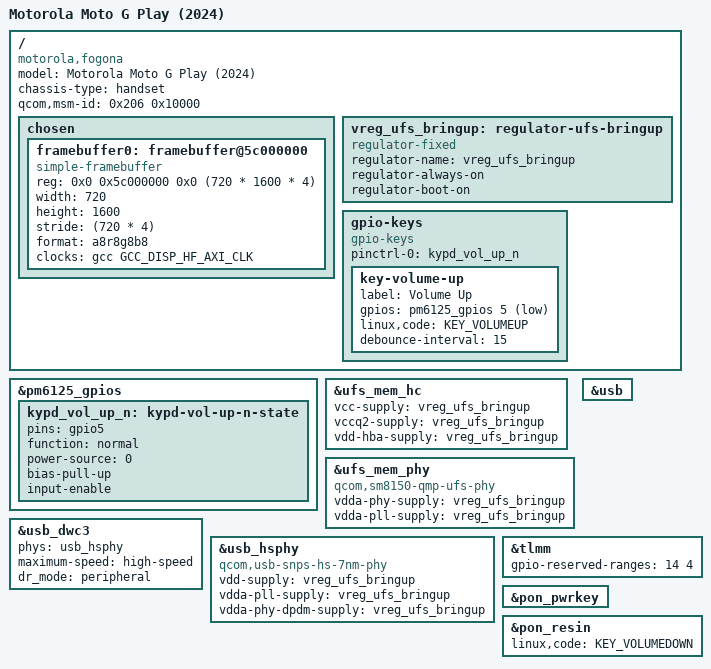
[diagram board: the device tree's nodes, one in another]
// SPDX-License-Identifier: BSD-3-Clause
/*
 * U-Boot board file: Motorola Moto G Play (2024) -- "fogona", SM6225 (khaje).
 *
 * Deliberately includes sm6115.dtsi and claims the sm6115 compatibles, because
 * U-Boot's Qualcomm support has clock-sm6115.c and pinctrl-sm6115.c and no
 * sm6225 equivalents. khaje is a bengal derivative, and mainline Linux's
 * gcc-sm6115 was confirmed to bind on this silicon (measured: it claimed the
 * clock controller at 0x1400000 and probed), so the same bet applies here.
 *
 * msm-id is measured, not inherited: /sys/devices/soc0/soc_id = 518 = 0x206,
 * revision 1.0. fogona ships two base DTBs differing only in this property
 * (0x24a and 0x206); this unit is 0x206.
 *
 * The framebuffer address is the same 0x5c000000 the fxtec sm6115 board uses,
 * confirmed on fogona from the live device tree
 * (splash_region@5c000000, 0xf00000) -- the panel is 720x1600 rather than
 * 1080x2160.
 */

/dts-v1/;

#include <dt-bindings/gpio/gpio.h>
#include <dt-bindings/input/linux-event-codes.h>
#include "sm6115.dtsi"
#include "pm6125.dtsi"

/ {
	model = "Motorola Moto G Play (2024)";
	compatible = "motorola,fogona", "qcom,sm6115";
	chassis-type = "handset";

	qcom,msm-id = <0x206 0x10000>;

	chosen {
		#address-cells = <2>;
		#size-cells = <2>;
		ranges;

		framebuffer0: framebuffer@5c000000 {
			compatible = "simple-framebuffer";
			reg = <0x0 0x5c000000 0x0 (720 * 1600 * 4)>;
			width = <720>;
			height = <1600>;
			stride = <(720 * 4)>;
			format = "a8r8g8b8";
			clocks = <&gcc GCC_DISP_HF_AXI_CLK>;
		};
	};
	/*
	 * UFS supplies. fogona's real rails are pm6125 LDOs behind RPM/SMD,
	 * which U-Boot has no driver for -- and ABL has already powered them,
	 * since it boots the device from UFS. An always-on fixed regulator is
	 * an honest stand-in for bringup.
	 */
	vreg_ufs_bringup: regulator-ufs-bringup {
		compatible = "regulator-fixed";
		regulator-name = "vreg_ufs_bringup";
		regulator-always-on;
		regulator-boot-on;
	};

	/*
	 * All three side keys are on the PM6125, none on TLMM. Power and
	 * volume-down come from the PON block (enabled at the end of this
	 * file); volume-up is PMIC GPIO 5.
	 *
	 * This node previously said <&tlmm 5>, which is the natural wrong
	 * guess and the one our Linux sm6225-motorola-fogona.dtsi explicitly
	 * warns about: the schematic routes KYPD_VOLP_N to PM6225 GPIO_05
	 * (pad 21), and the stock dtbo's vol_up node reads
	 * `gpios = <0xffffffff 0x05 0x01>` with a fixups block resolving that
	 * dangling phandle to pm6125_gpios. Read without applying the fixups
	 * it looks like a bare "gpio 5", and TLMM is the obvious misreading.
	 *
	 * Symptom of getting it wrong: volume-down works and volume-up does
	 * not, because down comes from PON and up reads a floating TLMM line.
	 *
	 * The pad also needs its pull-up: KYPD_VOLP_N is a switch to ground
	 * with no external pull, and the bootloader leaves the pad with the
	 * bias off, so the line floats while the key is up. Same state as
	 * the Linux dtsi, the stock dtbo (key_vol_up_default) and
	 * qrb4210-rb2.dts; the PMIC GPIO driver applies bias-pull-up and
	 * leaves it alone when the button driver later claims the line.
	 */
	gpio-keys {
		compatible = "gpio-keys";

		pinctrl-names = "default";
		pinctrl-0 = <&kypd_vol_up_n>;

		key-volume-up {
			label = "Volume Up";
			gpios = <&pm6125_gpios 5 GPIO_ACTIVE_LOW>;
			linux,code = <KEY_VOLUMEUP>;
			debounce-interval = <15>;
		};
	};
};

&pm6125_gpios {
	kypd_vol_up_n: kypd-vol-up-n-state {
		pins = "gpio5";
		function = "normal";
		power-source = <0>;
		bias-pull-up;
		input-enable;
	};
};

&ufs_mem_hc {
	vcc-supply = <&vreg_ufs_bringup>;
	vccq2-supply = <&vreg_ufs_bringup>;
	vdd-hba-supply = <&vreg_ufs_bringup>;
	status = "okay";
};

/*
 * Same class of mismatch as the USB HS PHY below: khaje's UFS QMP PHY is not
 * bengal's, and inheriting sm6115.dtsi gets us the wrong register tables.
 *
 * Unlike the USB case this one binds silently -- "qcom,sm6115-qmp-ufs-phy" IS
 * in U-Boot's match list, so the PHY programs without complaint and simply
 * never links, and `scsi scan` reports no devices with no error at all.
 *
 * Linux is explicit that these are different parts. In
 * phy-qcom-qmp-ufs.c, sm6125 aliases sm6115's config, but sm6225 gets its own:
 *
 *     sm6115: lanes 1, UFS_HS_G3, sm6115_ufsphy_* tables, v2 regs
 *     sm6225: lanes 2, UFS_HS_G4, sm8150_ufsphy_* tables, v4 regs
 *
 * and Linux's sm6225_ufsphy_cfg is field-for-field identical to its
 * sm8150_ufsphy_cfg -- a duplicated struct rather than a distinct PHY. U-Boot
 * has no "qcom,sm6225-qmp-ufs-phy", but it does carry sm8150_ufsphy_cfg with
 * the same 2 lanes, the same serdes/tx/rx/pcs tables and the same G4 overlay.
 *
 * So point at sm8150 and khaje gets exactly the tables Linux drives it with.
 * If a real qcom,sm6225-qmp-ufs-phy is ever added upstream, switch to it and
 * drop this override.
 */
&ufs_mem_phy {
	compatible = "qcom,sm8150-qmp-ufs-phy";
	vdda-phy-supply = <&vreg_ufs_bringup>;
	vdda-pll-supply = <&vreg_ufs_bringup>;
	status = "okay";
};

/*
 * USB. fogona is USB 2.0 only -- Motorola's schematics break out USB0_CC1/CC2
 * to testpoints but carry no SBU, and USB0_SS_* / USB0_DP_AUX_* have no
 * cross-sheet routing at all. So enable the HS phy and pin dwc3 to
 * high-speed, dropping the superspeed phy that sm6115.dtsi expects; otherwise
 * dwc3 waits on a qmpphy this board does not have.
 *
 * Supplies come from the bringup fixed regulator for the same reason as UFS:
 * the real rails are pm6125 LDOs behind RPM/SMD, and ABL has already brought
 * them up (it serves fastboot over this very port).
 */
&usb {
	status = "okay";
};

&usb_dwc3 {
	phys = <&usb_hsphy>;
	phy-names = "usb2-phy";
	maximum-speed = "high-speed";
	dr_mode = "peripheral";
};

/*
 * khaje's USB HS PHY is a Synopsys femto v2, NOT the QUSB2 that U-Boot's
 * sm6115.dtsi describes at this address.
 *
 * Including sm6115.dtsi is deliberate -- U-Boot has clock-sm6115.c and
 * pinctrl-sm6115.c and no sm6225 equivalents. That bet holds for clocks and
 * pinctrl. It does NOT hold for the USB PHY: bengal has a QUSB2 at 0x1613000,
 * khaje has a femto. Same address, same 0x180 window, different block.
 *
 * Inheriting "qcom,sm6115-qusb2-phy" binds phy-qcom-qusb2.c, which pokes
 * QUSB2 PLL registers that do not exist in this layout and fails with:
 *
 *     QUSSB2PHY pll lock failed; status reg = 0
 *     qcom-qusb2-phy phy@1613000: PHY: Failed to power on ...: -16
 *
 * Linux's own sm6225.dtsi and SCOS100's U-Boot sm6225.dtsi both declare
 * "qcom,sm6375-usb-hs-phy", "qcom,usb-snps-hs-7nm-phy" here, arrived at
 * independently. Override to the generic fallback, which
 * phy-qcom-snps-femto-v2.c matches and CONFIG_PHY_QCOM_USB_SNPS_FEMTO_V2
 * already builds.
 *
 * That driver takes only reg + reset -- no clocks, no supplies -- so this
 * also sidesteps both U-Boot gaps on khaje: no SMD/RPM regulator driver, and
 * rpmcc served by clk-stub. The supplies below are now vestigial; nothing
 * reads them. They are kept as documentation of the rails.
 */
&usb_hsphy {
	compatible = "qcom,usb-snps-hs-7nm-phy";
	vdd-supply = <&vreg_ufs_bringup>;
	vdda-pll-supply = <&vreg_ufs_bringup>;
	vdda-phy-dpdm-supply = <&vreg_ufs_bringup>;
	status = "okay";
};

/*
 * khaje reserves GPIOs 14-17. From Qualcomm's own downstream driver:
 *
 *   static const int khaje_reserved_gpios[] = { 14, 15, 16, 17, -1 };
 *       -- drivers/pinctrl/qcom/pinctrl-khaje.c
 *
 * Touching them during gpio init is what crashes TLMM on this SoC; it cost
 * another porter a day ("it would always crash at gpio init ... just had to
 * add the dummy pins to the reserved list and it boots"). ngpios stays 114,
 * which Qualcomm's driver, mainline pinctrl-sm6115 and the unmerged
 * pinctrl-sm6225 all agree on -- the datasheet's "GPIOs (125)" counts
 * something else, most likely PMIC GPIOs.
 */
&tlmm {
	gpio-reserved-ranges = <14 4>;
};

/*
 * Volume-down and power live on the PM6125's PON block, not on TLMM -- the
 * only TLMM key is volume-up (gpio 5). Without these, U-Boot prints
 * "No button labelled 'Volume Down'" and qcom-phone.env's bootmenu, which
 * binds volume-down to `run menucmd`, is unreachable.
 *
 * No driver work is needed: button-qcom-pmic.c already matches
 * qcom,pm8998-pon (the compatible pm6125.dtsi uses) and both child
 * compatibles, and CONFIG_BUTTON_QCOM_PMIC is enabled. Same wiring as
 * qrb4210-rb2.dts, which is also pm6125 on sm6115, and as our own Linux
 * sm6225-motorola-fogona.dtsi.
 */
&pon_pwrkey {
	status = "okay";
};

&pon_resin {
	linux,code = <KEY_VOLUMEDOWN>;
	status = "okay";
};
